AUTOSAR XML (schema 00046)
package /ComponentTypes
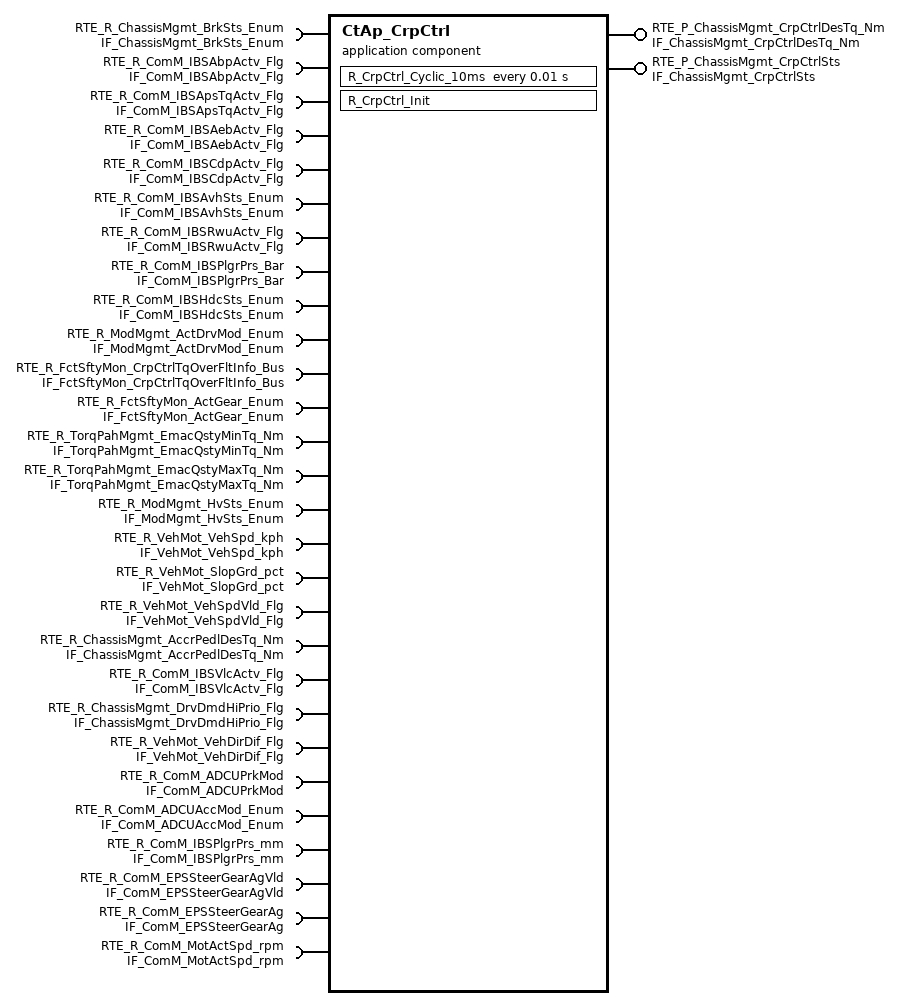
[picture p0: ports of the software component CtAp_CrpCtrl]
  application sw component type CtAp_CrpCtrl
    provide port RTE_P_ChassisMgmt_CrpCtrlDesTq_Nm: nonqueued-sender-com-spec{data-element=tec_ChassisMgmt_CrpCtrlDesTq_Nm, init-value=0}, provided-interface=IF_ChassisMgmt_CrpCtrlDesTq_Nm
    24 x require port:
      RTE_R_ChassisMgmt_BrkSts_Enum: nonqueued-receiver-com-spec{data-element=tec_ChassisMgmt_BrkSts_Enum, filter=data-filter-type=ALWAYS, init-value=0}, required-interface=IF_ChassisMgmt_BrkSts_Enum
      RTE_R_ComM_IBSAbpActv_Flg: nonqueued-receiver-com-spec{data-element=tec_ComM_IBSAbpActv_Flg, filter=data-filter-type=ALWAYS, init-value=0}, required-interface=IF_ComM_IBSAbpActv_Flg
      RTE_R_ComM_IBSApsTqActv_Flg: nonqueued-receiver-com-spec{data-element=tec_ComM_IBSApsTqActv_Flg, filter=data-filter-type=ALWAYS, init-value=0}, required-interface=IF_ComM_IBSApsTqActv_Flg
      RTE_R_ComM_IBSAebActv_Flg: nonqueued-receiver-com-spec{data-element=tec_ComM_IBSAebActv_Flg, filter=data-filter-type=ALWAYS, init-value=0}, required-interface=IF_ComM_IBSAebActv_Flg
      RTE_R_ComM_IBSCdpActv_Flg: nonqueued-receiver-com-spec{data-element=tec_ComM_IBSCdpActv_Flg, filter=data-filter-type=ALWAYS, init-value=0}, required-interface=IF_ComM_IBSCdpActv_Flg
      RTE_R_ComM_IBSAvhSts_Enum: nonqueued-receiver-com-spec{data-element=tec_ComM_IBSAvhSts_Enum, filter=data-filter-type=ALWAYS, init-value=0}, required-interface=IF_ComM_IBSAvhSts_Enum
      RTE_R_ComM_IBSRwuActv_Flg: nonqueued-receiver-com-spec{data-element=tec_ComM_IBSRwuActv_Flg, filter=data-filter-type=ALWAYS, init-value=0}, required-interface=IF_ComM_IBSRwuActv_Flg
      RTE_R_ComM_IBSPlgrPrs_Bar: nonqueued-receiver-com-spec{data-element=tec_ComM_IBSPlgrPrs_Bar, filter=data-filter-type=ALWAYS, init-value=0}, required-interface=IF_ComM_IBSPlgrPrs_Bar
      RTE_R_ComM_IBSHdcSts_Enum: nonqueued-receiver-com-spec{data-element=tec_ComM_IBSHdcSts_Enum, filter=data-filter-type=ALWAYS, init-value=0}, required-interface=IF_ComM_IBSHdcSts_Enum
      RTE_R_ModMgmt_ActDrvMod_Enum: nonqueued-receiver-com-spec{data-element=tec_ModMgmt_ActDrvMod_Enum, filter=data-filter-type=ALWAYS, init-value=0}, required-interface=IF_ModMgmt_ActDrvMod_Enum
      RTE_R_FctSftyMon_CrpCtrlTqOverFltInfo_Bus: nonqueued-receiver-com-spec{data-element=tec_FctSftyMon_CrpCtrlTqOverFltInfo_Bus, filter=data-filter-type=ALWAYS, init-value=fields=[FctSftyMon_MonStatCrpCtrlTqOverFltInfo:0, FctSftyMon_MonResCrpCtrlTqOverFltInfo:0, FctSftyMon_ErrStatCrpCtrlTqOverFltInfo:0, FctSftyMon_ErrResCrpCtrlTqOverFltInfo:0]}, required-interface=IF_FctSftyMon_CrpCtrlTqOverFltInfo_Bus
      RTE_R_FctSftyMon_ActGear_Enum: nonqueued-receiver-com-spec{data-element=tec_FctSftyMon_ActGear_Enum, filter=data-filter-type=ALWAYS, init-value=0}, required-interface=IF_FctSftyMon_ActGear_Enum
      RTE_R_TorqPahMgmt_EmacQstyMinTq_Nm: nonqueued-receiver-com-spec{data-element=tec_TorqPahMgmt_EmacQstyMinTq_Nm, filter=data-filter-type=ALWAYS, init-value=0}, required-interface=IF_TorqPahMgmt_EmacQstyMinTq_Nm
      RTE_R_TorqPahMgmt_EmacQstyMaxTq_Nm: nonqueued-receiver-com-spec{data-element=tec_TorqPahMgmt_EmacQstyMaxTq_Nm, filter=data-filter-type=ALWAYS, init-value=0}, required-interface=IF_TorqPahMgmt_EmacQstyMaxTq_Nm
      RTE_R_ModMgmt_HvSts_Enum: nonqueued-receiver-com-spec{data-element=tec_ModMgmt_HvSts_Enum, filter=data-filter-type=ALWAYS, init-value=0}, required-interface=IF_ModMgmt_HvSts_Enum
      RTE_R_VehMot_VehSpd_kph: nonqueued-receiver-com-spec{data-element=tec_VehMot_VehSpd_kph, filter=data-filter-type=ALWAYS, init-value=0}, required-interface=IF_VehMot_VehSpd_kph
      RTE_R_VehMot_SlopGrd_pct: nonqueued-receiver-com-spec{data-element=tec_VehMot_SlopGrd_pct, filter=data-filter-type=ALWAYS, init-value=0}, required-interface=IF_VehMot_SlopGrd_pct
      RTE_R_VehMot_VehSpdVld_Flg: nonqueued-receiver-com-spec{data-element=tec_VehMot_VehSpdVld_Flg, filter=data-filter-type=ALWAYS, init-value=0}, required-interface=IF_VehMot_VehSpdVld_Flg
      RTE_R_ChassisMgmt_AccrPedlDesTq_Nm: nonqueued-receiver-com-spec{data-element=tec_ChassisMgmt_AccrPedlDesTq_Nm, filter=data-filter-type=ALWAYS, init-value=0}, required-interface=IF_ChassisMgmt_AccrPedlDesTq_Nm
      RTE_R_ComM_IBSVlcActv_Flg: nonqueued-receiver-com-spec{data-element=tec_ComM_IBSVlcActv_Flg, filter=data-filter-type=ALWAYS, init-value=0}, required-interface=IF_ComM_IBSVlcActv_Flg
      RTE_R_ChassisMgmt_DrvDmdHiPrio_Flg: nonqueued-receiver-com-spec{data-element=tec_ChassisMgmt_DrvDmdHiPrio_Flg, filter=data-filter-type=ALWAYS, init-value=0}, required-interface=IF_ChassisMgmt_DrvDmdHiPrio_Flg
      RTE_R_VehMot_VehDirDif_Flg: nonqueued-receiver-com-spec{data-element=tec_VehMot_VehDirDif_Flg, filter=data-filter-type=ALWAYS, init-value=0}, required-interface=IF_VehMot_VehDirDif_Flg
      RTE_R_ComM_ADCUPrkMod: nonqueued-receiver-com-spec{data-element=tec_ComM_ADCUPrkMod, filter=data-filter-type=ALWAYS, init-value=0}, required-interface=IF_ComM_ADCUPrkMod
      RTE_R_ComM_ADCUAccMod_Enum: nonqueued-receiver-com-spec{data-element=tec_ComM_ADCUAccMod_Enum, filter=data-filter-type=ALWAYS, init-value=0}, required-interface=IF_ComM_ADCUAccMod_Enum
    provide port RTE_P_ChassisMgmt_CrpCtrlSts: nonqueued-sender-com-spec{data-element=tec_ChassisMgmt_CrpCtrlSts, init-value=0}, provided-interface=IF_ChassisMgmt_CrpCtrlSts
    4 x require port:
      RTE_R_ComM_IBSPlgrPrs_mm: nonqueued-receiver-com-spec{data-element=tec_ComM_IBSPlgrPrs_mm, filter=data-filter-type=ALWAYS, init-value=0}, required-interface=IF_ComM_IBSPlgrPrs_mm
      RTE_R_ComM_EPSSteerGearAgVld: nonqueued-receiver-com-spec{data-element=tec_ComM_EPSSteerGearAgVld, filter=data-filter-type=ALWAYS, init-value=0}, required-interface=IF_ComM_EPSSteerGearAgVld
      RTE_R_ComM_EPSSteerGearAg: nonqueued-receiver-com-spec{data-element=tec_ComM_EPSSteerGearAg, filter=data-filter-type=ALWAYS, init-value=0}, required-interface=IF_ComM_EPSSteerGearAg
      RTE_R_ComM_MotActSpd_rpm: nonqueued-receiver-com-spec{data-element=tec_ComM_MotActSpd_rpm, filter=data-filter-type=ALWAYS, init-value=0}, required-interface=IF_ComM_MotActSpd_rpm
    behavior CtAp_CrpCtrl_InternalBehavior
      timing event TMT_R_CrpCtrl_Cyclic_10ms: start-on-event=R_CrpCtrl_Cyclic_10ms, period=0.01
      init event CtAp_CrpCtrl_InitEvent: start-on-event=R_CrpCtrl_Init
      runnable R_CrpCtrl_Cyclic_10ms
        data-receive-point-by-arguments:
          28 x access:
            REC_RTE_R_ChassisMgmt_BrkSts_Enum_tec_ChassisMgmt_BrkSts_Enum: accessed-variable=RTE_R_ChassisMgmt_BrkSts_Enum.tec_ChassisMgmt_BrkSts_Enum
            REC_RTE_R_ComM_IBSAbpActv_Flg_tec_ComM_IBSAbpActv_Flg: accessed-variable=RTE_R_ComM_IBSAbpActv_Flg.tec_ComM_IBSAbpActv_Flg
            REC_RTE_R_ComM_IBSAebActv_Flg_tec_ComM_IBSAebActv_Flg: accessed-variable=RTE_R_ComM_IBSAebActv_Flg.tec_ComM_IBSAebActv_Flg
            REC_RTE_R_ComM_IBSApsTqActv_Flg_tec_ComM_IBSApsTqActv_Flg: accessed-variable=RTE_R_ComM_IBSApsTqActv_Flg.tec_ComM_IBSApsTqActv_Flg
            REC_RTE_R_ComM_IBSAvhSts_Enum_tec_ComM_IBSAvhSts_Enum: accessed-variable=RTE_R_ComM_IBSAvhSts_Enum.tec_ComM_IBSAvhSts_Enum
            REC_RTE_R_ComM_IBSCdpActv_Flg_tec_ComM_IBSCdpActv_Flg: accessed-variable=RTE_R_ComM_IBSCdpActv_Flg.tec_ComM_IBSCdpActv_Flg
            REC_RTE_R_ComM_IBSHdcSts_Enum_tec_ComM_IBSHdcSts_Enum: accessed-variable=RTE_R_ComM_IBSHdcSts_Enum.tec_ComM_IBSHdcSts_Enum
            REC_RTE_R_ComM_IBSRwuActv_Flg_tec_ComM_IBSRwuActv_Flg: accessed-variable=RTE_R_ComM_IBSRwuActv_Flg.tec_ComM_IBSRwuActv_Flg
            REC_RTE_R_FctSftyMon_ActGear_Enum_tec_FctSftyMon_ActGear_Enum: accessed-variable=RTE_R_FctSftyMon_ActGear_Enum.tec_FctSftyMon_ActGear_Enum
            REC_RTE_R_FctSftyMon_CrpCtrlTqOverFltInfo_Bus_tec_FctSftyMon_CrpCtrlTqOverFltInfo_Bus: accessed-variable=RTE_R_FctSftyMon_CrpCtrlTqOverFltInfo_Bus.tec_FctSftyMon_CrpCtrlTqOverFltInfo_Bus
            REC_RTE_R_ModMgmt_ActDrvMod_Enum_tec_ModMgmt_ActDrvMod_Enum: accessed-variable=RTE_R_ModMgmt_ActDrvMod_Enum.tec_ModMgmt_ActDrvMod_Enum
            REC_RTE_R_ModMgmt_HvSts_Enum_tec_ModMgmt_HvSts_Enum: accessed-variable=RTE_R_ModMgmt_HvSts_Enum.tec_ModMgmt_HvSts_Enum
            REC_RTE_R_TorqPahMgmt_EmacQstyMaxTq_Nm_tec_TorqPahMgmt_EmacQstyMaxTq_Nm: accessed-variable=RTE_R_TorqPahMgmt_EmacQstyMaxTq_Nm.tec_TorqPahMgmt_EmacQstyMaxTq_Nm
            REC_RTE_R_TorqPahMgmt_EmacQstyMinTq_Nm_tec_TorqPahMgmt_EmacQstyMinTq_Nm: accessed-variable=RTE_R_TorqPahMgmt_EmacQstyMinTq_Nm.tec_TorqPahMgmt_EmacQstyMinTq_Nm
            REC_RTE_R_VehMot_SlopGrd_pct_tec_VehMot_SlopGrd_pct: accessed-variable=RTE_R_VehMot_SlopGrd_pct.tec_VehMot_SlopGrd_pct
            REC_RTE_R_VehMot_VehSpdVld_Flg_tec_VehMot_VehSpdVld_Flg: accessed-variable=RTE_R_VehMot_VehSpdVld_Flg.tec_VehMot_VehSpdVld_Flg
            REC_RTE_R_VehMot_VehSpd_kph_tec_VehMot_VehSpd_kph: accessed-variable=RTE_R_VehMot_VehSpd_kph.tec_VehMot_VehSpd_kph
            REC_RTE_R_ChassisMgmt_AccrPedlDesTq_Nm_tec_ChassisMgmt_AccrPedlDesTq_Nm: accessed-variable=RTE_R_ChassisMgmt_AccrPedlDesTq_Nm.tec_ChassisMgmt_AccrPedlDesTq_Nm
            REC_RTE_R_ComM_IBSVlcActv_Flg_tec_ComM_IBSVlcActv_Flg: accessed-variable=RTE_R_ComM_IBSVlcActv_Flg.tec_ComM_IBSVlcActv_Flg
            REC_RTE_R_ChassisMgmt_DrvDmdHiPrio_Flg_tec_ChassisMgmt_DrvDmdHiPrio_Flg: accessed-variable=RTE_R_ChassisMgmt_DrvDmdHiPrio_Flg.tec_ChassisMgmt_DrvDmdHiPrio_Flg
            REC_RTE_R_ComM_ADCUAccMod_Enum_tec_ComM_ADCUAccMod_Enum: accessed-variable=RTE_R_ComM_ADCUAccMod_Enum.tec_ComM_ADCUAccMod_Enum
            REC_RTE_R_ComM_ADCUPrkMod_tec_ComM_ADCUPrkMod: accessed-variable=RTE_R_ComM_ADCUPrkMod.tec_ComM_ADCUPrkMod
            REC_RTE_R_VehMot_VehDirDif_Flg_tec_VehMot_VehDirDif_Flg: accessed-variable=RTE_R_VehMot_VehDirDif_Flg.tec_VehMot_VehDirDif_Flg
            REC_RTE_R_ComM_IBSPlgrPrs_tec_ComM_IBSPlgrPrs: accessed-variable=RTE_R_ComM_IBSPlgrPrs_mm.tec_ComM_IBSPlgrPrs_mm
            REC_RTE_R_ComM_IBSPlgrPrs_Bar_tec_ComM_IBSPlgrPrs_Bar: accessed-variable=RTE_R_ComM_IBSPlgrPrs_Bar.tec_ComM_IBSPlgrPrs_Bar
            REC_RTE_R_ComM_EPSSteerGearAgVld_tec_ComM_EPSSteerGearAgVld: accessed-variable=RTE_R_ComM_EPSSteerGearAgVld.tec_ComM_EPSSteerGearAgVld
            REC_RTE_R_ComM_EPSSteerGearAg_tec_ComM_EPSSteerGearAg: accessed-variable=RTE_R_ComM_EPSSteerGearAg.tec_ComM_EPSSteerGearAg
            REC_RTE_R_ComM_MotActSpd_rpm_tec_ComM_MotActSpd_rpm: accessed-variable=RTE_R_ComM_MotActSpd_rpm.tec_ComM_MotActSpd_rpm
        data-send-points:
          access SEND_RTE_P_ChassisMgmt_CrpCtrlDesTq_Nm_tec_ChassisMgmt_CrpCtrlDesTq_Nm: accessed-variable=RTE_P_ChassisMgmt_CrpCtrlDesTq_Nm.tec_ChassisMgmt_CrpCtrlDesTq_Nm
          access SEND_RTE_P_ChassisMgmt_CrpCtrlSts_tec_ChassisMgmt_CrpCtrlSts: accessed-variable=RTE_P_ChassisMgmt_CrpCtrlSts.tec_ChassisMgmt_CrpCtrlSts
      runnable R_CrpCtrl_Init
  swc implementation CtAp_CrpCtrl_Implementation: behavior=CtAp_CrpCtrl_InternalBehavior
